# MCXN947_cm33_core0 register map
Vendor: nxp.com; File version: 1.0
CPU: CM33 r2p0, little endian, MPU, FPU, VTOR, 3 interrupt priority bits
Registers are 32-bit, read-write, reset 0x0 unless marked. A register's access mark holds for its fields unless they carry their own. Offsets are from the block's base; [hi:lo] are bit positions.

## SM3_0 — SAFO_SM3_SGI
Base 0x40031000
0x200 DATIN0A reset not defined — Input Data register 0 lower-bank low
  [31:0] DATIN0A — Input Data register
0x204 DATIN0B reset not defined — Input Data register 0 lower-bank high
  [31:0] DATIN0B — Input Data register
0x208 DATIN0C reset not defined — Input Data register 0 upper-bank low
  [31:0] DATIN0C — Input Data register
0x20C DATIN0D reset not defined — Input Data register 0 upper-bank high
  [31:0] DATIN0D — Input Data register
0x210 DATIN1A reset not defined — Input Data register 1 lower-bank low
  [31:0] DATIN1A — Input Data register
0x214 DATIN1B reset not defined — Input Data register 1 lower-bank high
  [31:0] DATIN1B — Input Data register
0x218 DATIN1C reset not defined — Input Data register 1 upper-bank low
  [31:0] DATIN1C — Input Data register
0x21C DATIN1D reset not defined — Input Data register 1 upper-bank high
  [31:0] DATIN1D — Input Data register
0x240 KEY0A reset not defined — Input Key register 0 lower-bank low
  [31:0] KEY0A — Input Key register
0x244 KEY0B reset not defined — Input Key register 0 lower-bank high
  [31:0] KEY0B — Input Key register
0x248 KEY0C reset not defined — Input Key register 0 upper-bank low
  [31:0] KEY0C — Input Key register
0x24C KEY0D reset not defined — Input Key register 0 upper-bank high
  [31:0] KEY0D — Input Key register
0x250 KEY1A reset not defined — Input Key register 1 lower-bank low
  [31:0] KEY1A — Input Key register
0x254 KEY1B reset not defined — Input Key register 1 lower-bank high
  [31:0] KEY1B — Input Key register
0x258 KEY1C reset not defined — Input Key register 1 upper-bank low
  [31:0] KEY1C — Input Key register
0x25C KEY1D reset not defined — Input Key register 1 upper-bank high
  [31:0] KEY1D — Input Key register
0x2C0 DATOUTA ro reset not defined — Output Data register lower-bank low
  [31:0] DATOUTA — Output Data register
0x2C4 DATOUTB ro reset not defined — Ouput Data register lower-bank high
  [31:0] DATOUTB — Ouput Data register
0x2C8 DATOUTC ro reset not defined — Ouput Data register upper-bank low
  [31:0] DATOUTC — Ouput Data register
0x2CC DATOUTD ro reset not defined — Output Data register upper-bank high
  [31:0] DOUTD — Output Data register
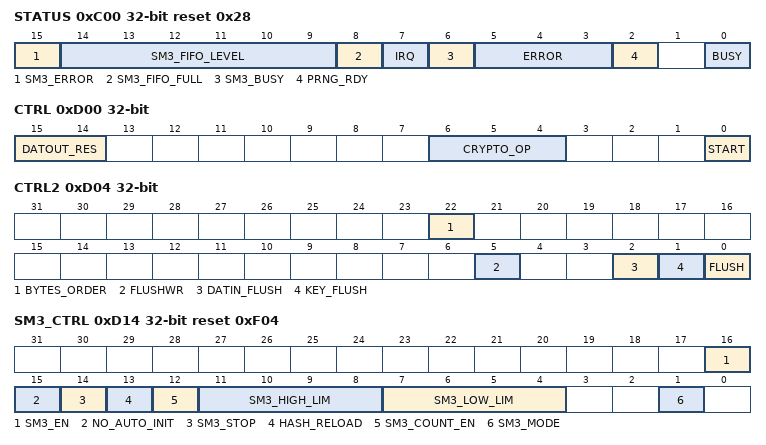
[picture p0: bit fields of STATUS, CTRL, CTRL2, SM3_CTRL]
0xC00 STATUS ro reset 0x28
  [15] SM3_ERROR
  [14:9] SM3_FIFO_LEVEL
  [8] SM3_FIFO_FULL — SM3 FIFO Full Indicator
  [7] IRQ — Interrupt Status Flag
  [6] SM3_BUSY — SM3 Busy Status Flag
  [5:3] ERROR — Error Indicator
  [2] PRNG_RDY — PRNG Ready
  [0] BUSY — Busy Flag
0xC04 COUNT — Calculation Counter
  [15:0] COUNT
0xD00 CTRL — SGI Control Register
  [15:14] DATOUT_RES — Kernels Data Out Options
  [6:4] CRYPTO_OP — Crypto Operation Type
  [0] START wo — Start Crypto Operation
0xD04 CTRL2 — SGI Control Register 2
  [22] BYTES_ORDER — Byte order of regbank read/write data
  [5] FLUSHWR — Flush Write control
  [2] DATIN_FLUSH wo — Start DATIN register-bank Flush
  [1] KEY_FLUSH wo — Start KEY register-bank Flush
  [0] FLUSH wo — Start Full SGI Flush
0xD14 SM3_CTRL reset 0xF04 — SM3 Control Register
  [16] SM3_EN — SM3 enable
  [15] NO_AUTO_INIT — SM3 no automatic HASH initialisation.
  [14] SM3_STOP — STOP SM3 AUTO mode
  [13] HASH_RELOAD — SM3 HASH reload
  [12] SM3_COUNT_EN — SM3 Calculation Counter Enable
  [11:8] SM3_HIGH_LIM — SM3 FIFO high limit
  [7:4] SM3_LOW_LIM — SM3 FIFO low limit
  [1] SM3_MODE wo — SM3 mode normal or automatic
0xD18 SM3_FIFO reset not defined
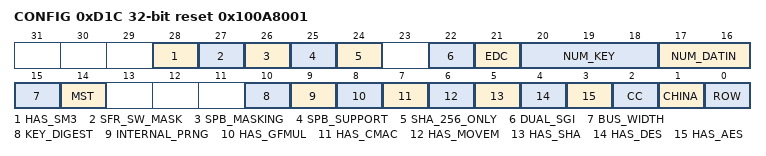
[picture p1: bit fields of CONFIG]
0xD1C CONFIG ro reset 0x100A8001 — SGI Configuration Register
  [28] HAS_SM3
  [27] SFR_SW_MASK — ID_CFG_SGI_USE_SFR_SW_MASK is set
  [26] SPB_MASKING — ID_CFG_SGI_SPB_MASKING is set
  [25] SPB_SUPPORT — ID_CFG_SPB_SUPPORT is set
  [24] SHA_256_ONLY — Has SHA 256 only
  [22] DUAL_SGI — Has dual SGI
  [21] EDC — EDC enable
  [20:18] NUM_KEY — Number KEY
  [17:16] NUM_DATIN — Number DATIN
  [15] BUS_WIDTH
  [14] MST — Has MST
  [10] KEY_DIGEST — Has key digest
  [9] INTERNAL_PRNG — Has internal PRNG
  [8] HAS_GFMUL
  [7] HAS_CMAC
  [6] HAS_MOVEM
  [5] HAS_SHA
  [4] HAS_DES
  [3] HAS_AES
  [2] CC
  [1] CHINA
  [0] ROW
0xFE4 INT_ENABLE — Interrupt Enable
  [0] INT_EN — Interrupt enable bit
0xFE8 INT_STATUS_CLR wo — Interrupt Status Clear
  [0] INT_CLR
0xFEC INT_STATUS_SET wo — Interrupt Status Set
  [0] INT_SET — Set Interrupt by SW
